AUTOSAR XML (schema 4-0-3)
package /ComponentTypes
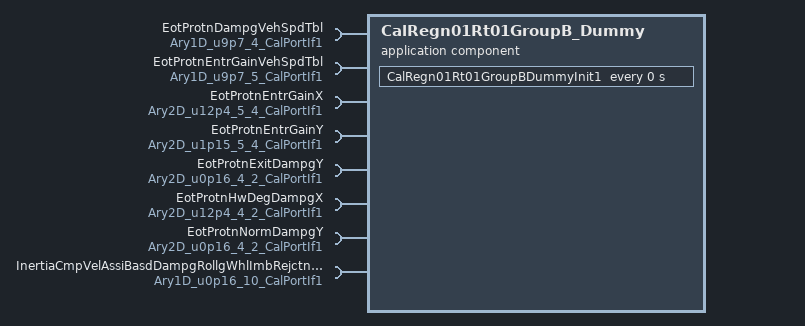
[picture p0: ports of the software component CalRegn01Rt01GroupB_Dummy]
  application sw component type CalRegn01Rt01GroupB_Dummy
    8 x require port:
      EotProtnDampgVehSpdTbl: parameter-require-com-spec{init-value=[0, 640, 1280, 2560], parameter=Ary1D}, required-interface=Ary1D_u9p7_4_CalPortIf1
      EotProtnEntrGainVehSpdTbl: parameter-require-com-spec{init-value=[0, 640, 1280, 1920, 2560], parameter=Ary1D}, required-interface=Ary1D_u9p7_5_CalPortIf1
      EotProtnEntrGainX: parameter-require-com-spec{init-value=5 x [0, 480, 960, 1440], parameter=Ary2D}, required-interface=Ary2D_u12p4_5_4_CalPortIf1
      EotProtnEntrGainY: parameter-require-com-spec{init-value=5 x [0, 10813, 21627, 32768], parameter=Ary2D}, required-interface=Ary2D_u1p15_5_4_CalPortIf1
      EotProtnExitDampgY: parameter-require-com-spec{init-value=[[0, 262], [0, 262], [0, 262], [0, 262]], parameter=Ary2D}, required-interface=Ary2D_u0p16_4_2_CalPortIf1
      EotProtnHwDegDampgX: parameter-require-com-spec{init-value=[[1920, 0], [1920, 0], [1920, 0], [1920, 0]], parameter=Ary2D}, required-interface=Ary2D_u12p4_4_2_CalPortIf1
      EotProtnNormDampgY: parameter-require-com-spec{init-value=[[0, 262], [0, 262], [0, 262], [0, 262]], parameter=Ary2D}, required-interface=Ary2D_u0p16_4_2_CalPortIf1
      InertiaCmpVelAssiBasdDampgRollgWhlImbRejctnOnY: parameter-require-com-spec{init-value=10 x 0, parameter=Ary1D}, required-interface=Ary1D_u0p16_10_CalPortIf1
    behavior CalRegn01Rt01GroupB_Dummy_InternalBehavior: supports-multiple-instantiation=true
      timing event CalRegn01Rt01GroupB_Dummy_InitEvent: start-on-event=CalRegn01Rt01GroupBDummyInit1, period=0
      runnable CalRegn01Rt01GroupBDummyInit1
  swc implementation CalRegn01Rt01GroupBDummy_Implementation: behavior=CalRegn01Rt01GroupB_Dummy_InternalBehavior
    code-descriptors:
      code Default: artifact-descriptors=autosar-engineering-object={short-label=Default, category=SWSRC}
